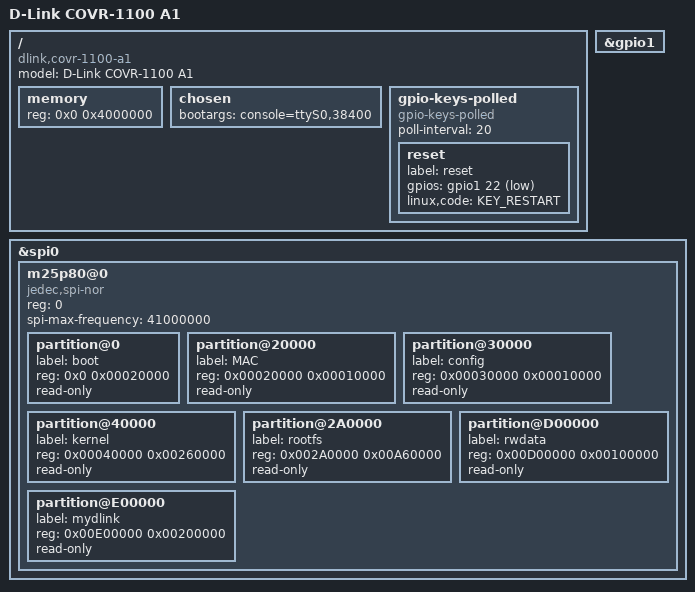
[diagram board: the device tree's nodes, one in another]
// SPDX-License-Identifier: GPL-2.0
/dts-v1/;

#include "RTL8197F.dtsi"

#include <dt-bindings/gpio/gpio.h>
#include <dt-bindings/input/input.h>

/ {
	compatible = "dlink,covr-1100-a1", "realtek,rtl8197f-soc";
	model = "D-Link COVR-1100 A1";

	memory {
		device_type = "memory";
		reg = <0x0 0x4000000>;
	};

	chosen {
		bootargs = "console=ttyS0,38400";
	};

	gpio-keys-polled {
		compatible = "gpio-keys-polled";
		#address-cells = <1>;
		#size-cells = <0>;
		poll-interval = <20>;

		reset {
			label = "reset";
			gpios = <&gpio1 22 GPIO_ACTIVE_LOW>;
			linux,code = <KEY_RESTART>;
		};
	};

	// Breaks device switch. Still needs fix before using it
	// gpio-leds {
	// 	compatible = "gpio-leds";

	// 	wps {
	// 		label = "re708:green:wps";
	// 		gpios = <&gpio1 25 GPIO_ACTIVE_LOW>;
	// 	};
	// };

};

&gpio1 {
	status = "okay";
};

&spi0 {
	status = "okay";

	m25p80@0 {
		#address-cells = <1>;
		#size-cells = <1>;
		compatible = "jedec,spi-nor";
		reg = <0>;
		spi-max-frequency = <41000000>;

		partition@0 {
			label = "boot";
			reg = <0x0 0x00020000>;
			read-only;
		};

		partition@20000 {
			label = "MAC";
			reg = <0x00020000 0x00010000>;
			read-only;
		};

		partition@30000 {
			label = "config";
			reg = <0x00030000 0x00010000>;
			read-only;
		};

		partition@40000 {
			label = "kernel";
			reg = <0x00040000 0x00260000>;
			read-only;
		};

		partition@2A0000 {
			label = "rootfs";
			reg = <0x002A0000 0x00A60000>;
			read-only;
		};

//		partition@40000 {
//			label = "Linux";
//			reg = <0x00040000 0x00CC0000>;
//			read-only;
//		};

		partition@D00000 {
			label = "rwdata";
			reg = <0x00D00000 0x00100000>;
			read-only;
		};

		partition@E00000 {
			label = "mydlink";
			reg = <0x00E00000 0x00200000>;
			read-only;
		};

//		partition@0 {
//			label = "ALL";
//			reg = <0x0 0x01000000>;
//			read-only;
//		};
	};
};
